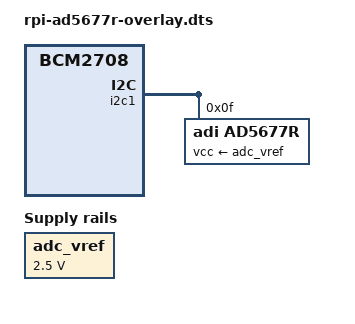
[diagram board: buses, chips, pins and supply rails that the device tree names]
// SPDX-License-Identifier: GPL-2.0
/dts-v1/;
/plugin/;

/ {
	compatible = "brcm,bcm2708";

	fragment@0 {
		target-path = "/";
		__overlay__ {
			adc_vref: fixedregulator@0 {
				compatible = "regulator-fixed";
				regulator-name = "fixed-supply";
				regulator-min-microvolt = <2500000>;
				regulator-max-microvolt = <2500000>;
				regulator-boot-on;
			};
		};
	};

	fragment@1 {
		target = <&i2c1>;
		__overlay__ {
			#address-cells = <1>;
			#size-cells = <0>;
			status = "okay";

			ad5677r@0f{
				compatible = "adi,ad5677r";
				reg = <0x0f>;
				vcc-supply = <&adc_vref>;
			};
		};
	};
};
